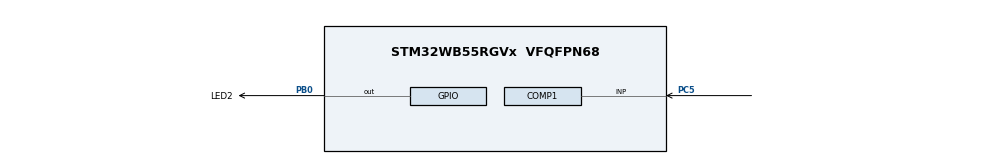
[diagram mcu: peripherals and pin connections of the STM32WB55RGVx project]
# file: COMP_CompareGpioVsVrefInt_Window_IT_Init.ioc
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COMP1.BlankingSrce=COMP_BLANKINGSRC_NONE
COMP1.Hysteresis=COMP_HYSTERESIS_NONE
COMP1.Mode=COMP_POWERMODE_MEDIUMSPEED
COMP1.OutputPol=COMP_OUTPUTPOL_NONINVERTED
COMP1.TriggerMode=COMP_TRIGGERMODE_IT_RISING_FALLING
COMP2.BlankingSrce=COMP_BLANKINGSRC_NONE
COMP2.Hysteresis=COMP_HYSTERESIS_LOW
COMP2.Mode=COMP_POWERMODE_MEDIUMSPEED
COMP2.OutputPol=COMP_OUTPUTPOL_NONINVERTED
COMP2.TriggerMode=COMP_TRIGGERMODE_IT_RISING_FALLING
COMP2.WindowMode=COMP_WINDOWMODE_COMP1_INPUT_PLUS_COMMON
Mcu.Family=STM32WB
Mcu.Name=STM32WB55RGVx
Mcu.Package=VFQFPN68
NVIC.COMP_IRQn=true\:0\:0\:false\:false\:true\:false\:true
NVIC.PriorityGroup=NVIC_PRIORITYGROUP_4
PB0.GPIO_Label=LED2
PB0.Signal=GPIO_Output
PC5.Mode=INP
PC5.Signal=COMP1_INP
ProjectManager.HeapSize=0x200
ProjectManager.StackSize=0x400
ProjectManager.TargetToolchain=EWARM V8
RCC.ADCFreq_Value=16000000
RCC.AHB2CLKDivider=RCC_SYSCLK_DIV2
RCC.AHBFreq_Value=16000000
RCC.APB1Freq_Value=16000000
RCC.APB1TimFreq_Value=16000000
RCC.APB2Freq_Value=16000000
RCC.APB2TimFreq_Value=16000000
RCC.APB3Freq_Value=16000000
RCC.CodegenConfigPeriph=false
RCC.CortexFreq_Value=16000000
RCC.HCLKFreq_Value=16000000
RCC.HSE_VALUE=8000000
RCC.HSI48_VALUE=48000000
RCC.HSI_VALUE=16000000
RCC.LSE_VALUE=32768
RCC.PLLN=32
RCC.SYSCLKFreq_VALUE=16000000
RCC.SYSCLKSource=RCC_SYSCLKSOURCE_HSI
RCC.USBFreq_Value=16000000
RCC.VCOOutputFreq_Value=128000000
VP_COMP1_VS_VREFINT.Mode=VREFINT
VP_COMP2_VS_VREFINT12.Mode=VREFINT_12
VP_COMP2_VS_WindowMode.Mode=WindowMode
board=custom

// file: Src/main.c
/* USER CODE BEGIN Header */
/**
  ******************************************************************************
  * @file    Examples_LL/COMP/COMP_CompareGpioVsVrefInt_Window_IT_Init/Src/main.c
  * @author  MCD Application Team
  * @brief   This example shows how to use a pair of comparator peripherals
  *          to compare a voltage level applied on a GPIO pin
  *          versus 2 thresholds: the internal voltage reference (VrefInt)
  *          and a fraction the internal voltage reference (VrefInt/2),
  *          in interrupt mode.
  *          This example is based on the STM32WBxx COMP LL API;
  *          Peripheral initialization done using LL unitary services functions.
  ******************************************************************************
  * @attention
  *
  * <h2><center>&copy; Copyright (c) 2019 STMicroelectronics.
  * All rights reserved.</center></h2>
  *
  * This software component is licensed by ST under BSD 3-Clause license,
  * the "License"; You may not use this file except in compliance with the
  * License. You may obtain a copy of the License at:
  *                        opensource.org/licenses/BSD-3-Clause
  *
  ******************************************************************************
  */
/* USER CODE END Header */

#include "main.h"

void SystemClock_Config(void);
static void MX_GPIO_Init(void);
static void MX_COMP1_Init(void);
static void MX_COMP2_Init(void);
/* USER CODE BEGIN PFP */
void     SystemClock_Config(void);
void     Activate_COMP_master_slave(void);
void     LED_On(void);
void     LED_Off(void);
/* USER CODE END PFP */

int main(void)
{

  /* MCU Configuration--------------------------------------------------------*/

  /* Reset of all peripherals, Initializes the Flash interface and the Systick. */

  NVIC_SetPriorityGrouping(NVIC_PRIORITYGROUP_4);

  /* System interrupt init*/

  /* Configure the system clock */
  SystemClock_Config();

  /* Initialize all configured peripherals */
  MX_GPIO_Init();
  MX_COMP1_Init();
  MX_COMP2_Init();
  /* USER CODE BEGIN 2 */

  /* Activate pair of comparators */
  Activate_COMP_master_slave();

  /* Lock comparator instance */
  //LL_COMP_Lock(COMP1);

  /* USER CODE END 2 */

  /* Infinite loop */
  /* USER CODE BEGIN WHILE */
  while (1)
  {
    /* Note: LED state depending on COMP status is set into COMP IRQ handler, */
    /*        refer to function "ComparatorTrigger_Callback()".               */

    /* USER CODE END WHILE */

  }
}

void SystemClock_Config(void)
{
  /* HSI configuration and activation */
  LL_RCC_HSI_Enable();
  while(LL_RCC_HSI_IsReady() != 1)
  {
  };

  /* Sysclk activation on the HSI */
  /* Set CPU1 prescaler*/
  LL_RCC_SetAHBPrescaler(LL_RCC_SYSCLK_DIV_1);

  /* Set CPU2 prescaler*/
  LL_C2_RCC_SetAHBPrescaler(LL_RCC_SYSCLK_DIV_2);

  LL_RCC_SetSysClkSource(LL_RCC_SYS_CLKSOURCE_HSI);
  while(LL_RCC_GetSysClkSource() != LL_RCC_SYS_CLKSOURCE_STATUS_HSI)
  {
  };

  /* Set AHB SHARED prescaler*/
  LL_RCC_SetAHB4Prescaler(LL_RCC_SYSCLK_DIV_1);

  /* Set APB1 prescaler*/
  LL_RCC_SetAPB1Prescaler(LL_RCC_APB1_DIV_1);

  /* Set APB2 prescaler*/
  LL_RCC_SetAPB2Prescaler(LL_RCC_APB2_DIV_1);

  LL_Init1msTick(16000000);

  /* Update CMSIS variable (which can be updated also through SystemCoreClockUpdate function) */
  LL_SetSystemCoreClock(16000000);
}

static void MX_COMP1_Init(void)
{

  LL_COMP_InitTypeDef COMP_InitStruct = {0};

  LL_GPIO_InitTypeDef GPIO_InitStruct = {0};

  LL_AHB2_GRP1_EnableClock(LL_AHB2_GRP1_PERIPH_GPIOC);
  /**COMP1 GPIO Configuration
  PC5   ------> COMP1_INP
  */
  GPIO_InitStruct.Pin = LL_GPIO_PIN_5;
  GPIO_InitStruct.Mode = LL_GPIO_MODE_ANALOG;
  GPIO_InitStruct.Pull = LL_GPIO_PULL_NO;
  LL_GPIO_Init(GPIOC, &GPIO_InitStruct);

  /* COMP1 interrupt Init */
  NVIC_SetPriority(COMP_IRQn, NVIC_EncodePriority(NVIC_GetPriorityGrouping(),0, 0));
  NVIC_EnableIRQ(COMP_IRQn);

  COMP_InitStruct.PowerMode = LL_COMP_POWERMODE_MEDIUMSPEED;
  COMP_InitStruct.InputPlus = LL_COMP_INPUT_PLUS_IO1;
  COMP_InitStruct.InputMinus = LL_COMP_INPUT_MINUS_VREFINT;
  COMP_InitStruct.InputHysteresis = LL_COMP_HYSTERESIS_NONE;
  COMP_InitStruct.OutputPolarity = LL_COMP_OUTPUTPOL_NONINVERTED;
  COMP_InitStruct.OutputBlankingSource = LL_COMP_BLANKINGSRC_NONE;
  LL_COMP_Init(COMP1, &COMP_InitStruct);
  LL_COMP_SetCommonWindowMode(__LL_COMP_COMMON_INSTANCE(COMP1), LL_COMP_WINDOWMODE_DISABLE);

  /* Wait loop initialization and execution */
  /* Note: Variable divided by 2 to compensate partially CPU processing cycles */
  __IO uint32_t wait_loop_index = 0;
  wait_loop_index = (LL_COMP_DELAY_VOLTAGE_SCALER_STAB_US * (SystemCoreClock / (1000000 * 2)));
  while(wait_loop_index != 0)
  {
    wait_loop_index--;
  }
  LL_EXTI_ClearFlag_0_31(LL_EXTI_LINE_20);
  LL_EXTI_EnableFallingTrig_0_31(LL_EXTI_LINE_20);
  LL_EXTI_EnableRisingTrig_0_31(LL_EXTI_LINE_20);
  LL_EXTI_DisableEvent_0_31(LL_EXTI_LINE_20);
  LL_EXTI_EnableIT_0_31(LL_EXTI_LINE_20);

}

static void MX_COMP2_Init(void)
{

  LL_COMP_InitTypeDef COMP_InitStruct = {0};

  /* COMP2 interrupt Init */
  NVIC_SetPriority(COMP_IRQn, NVIC_EncodePriority(NVIC_GetPriorityGrouping(),0, 0));
  NVIC_EnableIRQ(COMP_IRQn);

  COMP_InitStruct.PowerMode = LL_COMP_POWERMODE_MEDIUMSPEED;
  COMP_InitStruct.InputPlus = LL_COMP_INPUT_PLUS_IO1;
  COMP_InitStruct.InputMinus = LL_COMP_INPUT_MINUS_1_2VREFINT;
  COMP_InitStruct.InputHysteresis = LL_COMP_HYSTERESIS_LOW;
  COMP_InitStruct.OutputPolarity = LL_COMP_OUTPUTPOL_NONINVERTED;
  COMP_InitStruct.OutputBlankingSource = LL_COMP_BLANKINGSRC_NONE;
  LL_COMP_Init(COMP2, &COMP_InitStruct);
  LL_COMP_SetCommonWindowMode(__LL_COMP_COMMON_INSTANCE(COMP2), LL_COMP_WINDOWMODE_COMP1_INPUT_PLUS_COMMON);

  /* Wait loop initialization and execution */
  /* Note: Variable divided by 2 to compensate partially CPU processing cycles */
  __IO uint32_t wait_loop_index = 0;
  wait_loop_index = (LL_COMP_DELAY_VOLTAGE_SCALER_STAB_US * (SystemCoreClock / (1000000 * 2)));
  while(wait_loop_index != 0)
  {
    wait_loop_index--;
  }
  LL_EXTI_ClearFlag_0_31(LL_EXTI_LINE_21);
  LL_EXTI_EnableFallingTrig_0_31(LL_EXTI_LINE_21);
  LL_EXTI_EnableRisingTrig_0_31(LL_EXTI_LINE_21);
  LL_EXTI_DisableEvent_0_31(LL_EXTI_LINE_21);
  LL_EXTI_EnableIT_0_31(LL_EXTI_LINE_21);

}

static void MX_GPIO_Init(void)
{
  LL_GPIO_InitTypeDef GPIO_InitStruct = {0};

  /* GPIO Ports Clock Enable */
  LL_AHB2_GRP1_EnableClock(LL_AHB2_GRP1_PERIPH_GPIOC);
  LL_AHB2_GRP1_EnableClock(LL_AHB2_GRP1_PERIPH_GPIOB);

  /**/
  LL_GPIO_ResetOutputPin(LED2_GPIO_Port, LED2_Pin);

  /**/
  GPIO_InitStruct.Pin = LED2_Pin;
  GPIO_InitStruct.Mode = LL_GPIO_MODE_OUTPUT;
  GPIO_InitStruct.Speed = LL_GPIO_SPEED_FREQ_LOW;
  GPIO_InitStruct.OutputType = LL_GPIO_OUTPUT_PUSHPULL;
  GPIO_InitStruct.Pull = LL_GPIO_PULL_NO;
  LL_GPIO_Init(LED2_GPIO_Port, &GPIO_InitStruct);

}

/* USER CODE BEGIN 4 */

/**
  * @brief  Perform comparator activation procedure of the pair of comparators
  *         for window mode (COMP instances: COMP1, COMP2).
  * @note   Operations:
  *         - Enable comparator instance master
  *         - Enable comparator instance slave
  *         - Wait for comparator startup time
  *           (required to reach propagation delay specification)
  * @param  None
  * @retval None
  */
void Activate_COMP_master_slave(void)
{
  __IO uint32_t wait_loop_index = 0;

  /* Enable comparator instance master */
  LL_COMP_Enable(COMP1);

  /* Enable comparator instance slave */
  LL_COMP_Enable(COMP2);

  /* Delay for comparator startup time.                                       */
  /* Compute number of CPU cycles to wait for, from delay in us.              */
  /* Note: Variable divided by 2 to compensate partially                      */
  /*       CPU processing cycles (depends on compilation optimization).       */
  /* Note: If system core clock frequency is below 200kHz, wait time          */
  /*       is only a few CPU processing cycles.                               */
  wait_loop_index = ((LL_COMP_DELAY_STARTUP_US * (SystemCoreClock / (100000 * 2))) / 10);
  while(wait_loop_index != 0)
  {
    wait_loop_index--;
  }

}

/**
  * @brief  Turn-on LED2.
  * @param  None
  * @retval None
  */
void LED_On(void)
{
  /* Turn LED2 on */
  LL_GPIO_SetOutputPin(LED2_GPIO_Port, LED2_Pin);
}

/**
  * @brief  Turn-off LED2.
  * @param  None
  * @retval None
  */
void LED_Off(void)
{
  /* Turn LED2 off */
  LL_GPIO_ResetOutputPin(LED2_GPIO_Port, LED2_Pin);
}

/******************************************************************************/
/*   USER IRQ HANDLER TREATMENT                                               */
/******************************************************************************/

/**
  * @brief  Comparator interruption callback
  *         This function is executed when the comparator threshold
  *         is triggered.
  * @retval None
  */
void ComparatorTrigger_Callback()
{
  __IO uint32_t COMP1OutputLevel = LL_COMP_ReadOutputLevel(COMP1);
  __IO uint32_t COMP2OutputLevel = LL_COMP_ReadOutputLevel(COMP2);

  /* Set LED state in function of comparator output level */
  /* Case of voltage above comparators thresholds window */
  if (   (COMP1OutputLevel == LL_COMP_OUTPUT_LEVEL_LOW)
      && (COMP2OutputLevel == LL_COMP_OUTPUT_LEVEL_LOW)
     )
  {
    LED_Off();
  }
  /* Case of voltage below comparators thresholds window */
  else if (   (COMP1OutputLevel == LL_COMP_OUTPUT_LEVEL_HIGH)
           && (COMP2OutputLevel == LL_COMP_OUTPUT_LEVEL_HIGH)
     )
  {
    LED_Off();
  }
  /* Case of voltage inside comparators thresholds window */
  else /* COMP1 output high, COMP2 output low */
  {
    LED_On();
  }
}

/* USER CODE END 4 */

void Error_Handler(void)
{
}

/************************ (C) COPYRIGHT STMicroelectronics *****END OF FILE****/
